AUTOSAR XML (schema 4-2-1)
package /ComponentTypes
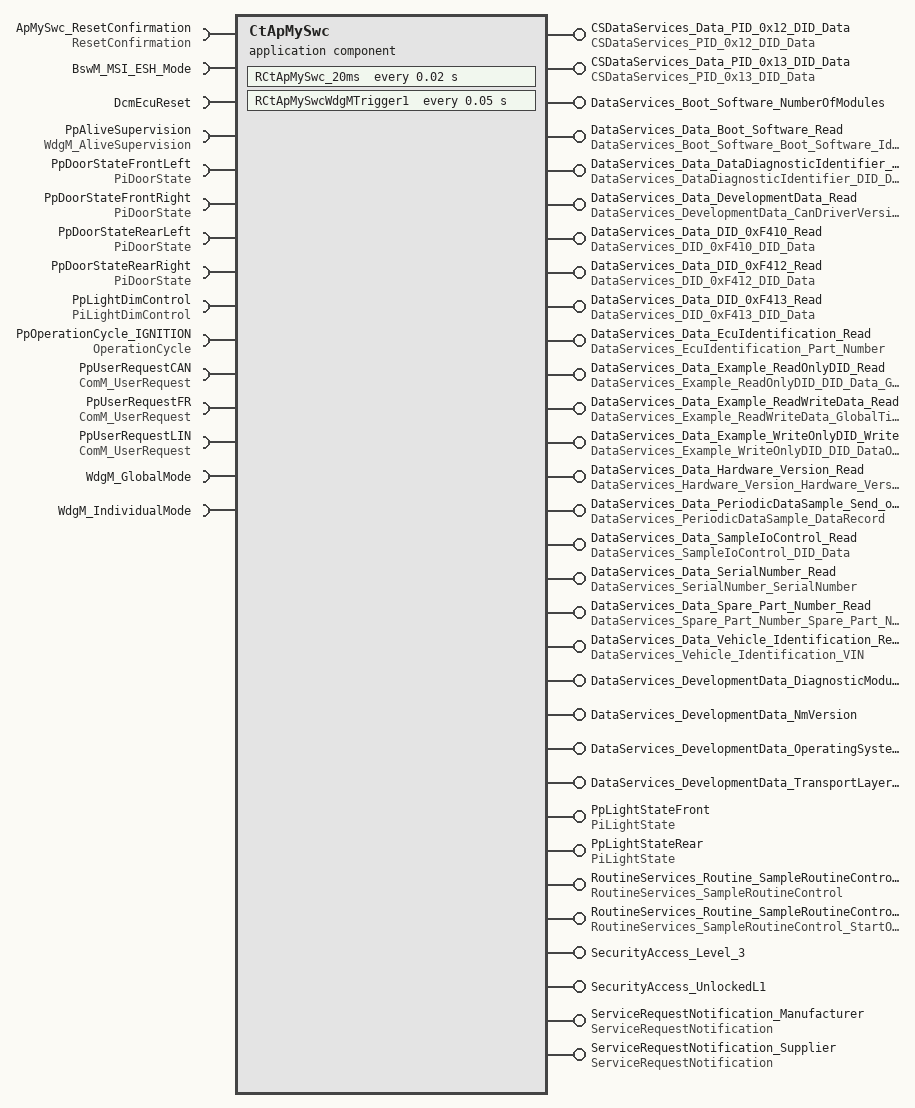
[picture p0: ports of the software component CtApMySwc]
  application sw component type CtApMySwc
    31 x provide port:
      CSDataServices_Data_PID_0x12_DID_Data: server-com-spec{operation=ReadData, queue-length=1}, provided-interface=CSDataServices_PID_0x12_DID_Data
      CSDataServices_Data_PID_0x13_DID_Data: server-com-spec{operation=ReadData, queue-length=1}, provided-interface=CSDataServices_PID_0x13_DID_Data
      DataServices_Boot_Software_NumberOfModules: provided-interface=DataServices_Boot_Software_NumberOfModules
        provided-com-specs:
          operation=ConditionCheckRead, queue-length=1
          operation=ReadData, queue-length=1
          operation=WriteData, queue-length=1
      DataServices_Data_Boot_Software_Read: provided-interface=DataServices_Boot_Software_Boot_Software_Identification
        provided-com-specs:
          operation=ConditionCheckRead, queue-length=1
          operation=ReadData, queue-length=1
          operation=WriteData, queue-length=1
      DataServices_Data_DataDiagnosticIdentifier_DID_Read: provided-interface=DataServices_DataDiagnosticIdentifier_DID_DataDiagnosticIdentifier
        provided-com-specs:
          operation=ConditionCheckRead, queue-length=1
          operation=ReadData, queue-length=1
          operation=WriteData, queue-length=1
      DataServices_Data_DevelopmentData_Read: provided-interface=DataServices_DevelopmentData_CanDriverVersion
        provided-com-specs:
          operation=ConditionCheckRead, queue-length=1
          operation=ReadData, queue-length=1
          operation=WriteData, queue-length=1
      DataServices_Data_DID_0xF410_Read: provided-com-specs=[{operation=ConditionCheckRead, queue-length=1}, {operation=ReadData, queue-length=1}], provided-interface=DataServices_DID_0xF410_DID_Data
      DataServices_Data_DID_0xF412_Read: provided-com-specs=[{operation=ConditionCheckRead, queue-length=1}, {operation=ReadData, queue-length=1}], provided-interface=DataServices_DID_0xF412_DID_Data
      DataServices_Data_DID_0xF413_Read: provided-com-specs=[{operation=ConditionCheckRead, queue-length=1}, {operation=ReadData, queue-length=1}], provided-interface=DataServices_DID_0xF413_DID_Data
      DataServices_Data_EcuIdentification_Read: provided-interface=DataServices_EcuIdentification_Part_Number
        provided-com-specs:
          operation=ConditionCheckRead, queue-length=1
          operation=ReadData, queue-length=1
          operation=WriteData, queue-length=1
      DataServices_Data_Example_ReadOnlyDID_Read: provided-com-specs=[{operation=ConditionCheckRead, queue-length=1}, {operation=ReadData, queue-length=1}], provided-interface=DataServices_Example_ReadOnlyDID_DID_Data_GlobalTime
      DataServices_Data_Example_ReadWriteData_Read: provided-interface=DataServices_Example_ReadWriteData_GlobalTime
        provided-com-specs:
          operation=ConditionCheckRead, queue-length=1
          operation=ReadData, queue-length=1
          operation=WriteData, queue-length=1
      DataServices_Data_Example_WriteOnlyDID_Write: server-com-spec{operation=WriteData, queue-length=1}, provided-interface=DataServices_Example_WriteOnlyDID_DID_DataObject
      DataServices_Data_Hardware_Version_Read: provided-interface=DataServices_Hardware_Version_Hardware_Version_Number
        provided-com-specs:
          operation=ConditionCheckRead, queue-length=1
          operation=ReadData, queue-length=1
          operation=WriteData, queue-length=1
      DataServices_Data_PeriodicDataSample_Send_once: provided-com-specs=[{operation=ConditionCheckRead, queue-length=1}, {operation=ReadData, queue-length=1}], provided-interface=DataServices_PeriodicDataSample_DataRecord
      DataServices_Data_SampleIoControl_Read: provided-interface=DataServices_SampleIoControl_DID_Data
        provided-com-specs:
          operation=FreezeCurrentState, queue-length=1
          operation=ReadData, queue-length=1
          operation=ResetToDefault, queue-length=1
          operation=ReturnControlToECU, queue-length=1
          operation=ShortTermAdjustment, queue-length=1
      DataServices_Data_SerialNumber_Read: provided-interface=DataServices_SerialNumber_SerialNumber
        provided-com-specs:
          operation=ConditionCheckRead, queue-length=1
          operation=ReadData, queue-length=1
          operation=WriteData, queue-length=1
      DataServices_Data_Spare_Part_Number_Read: provided-interface=DataServices_Spare_Part_Number_Spare_Part_Number
        provided-com-specs:
          operation=ConditionCheckRead, queue-length=1
          operation=ReadData, queue-length=1
          operation=WriteData, queue-length=1
      DataServices_Data_Vehicle_Identification_Read: provided-interface=DataServices_Vehicle_Identification_VIN
        provided-com-specs:
          operation=ConditionCheckRead, queue-length=1
          operation=ReadData, queue-length=1
          operation=WriteData, queue-length=1
      DataServices_DevelopmentData_DiagnosticModuleVersion: provided-interface=DataServices_DevelopmentData_DiagnosticModuleVersion
        provided-com-specs:
          operation=ConditionCheckRead, queue-length=1
          operation=ReadData, queue-length=1
          operation=WriteData, queue-length=1
      DataServices_DevelopmentData_NmVersion: provided-interface=DataServices_DevelopmentData_NmVersion
        provided-com-specs:
          operation=ConditionCheckRead, queue-length=1
          operation=ReadData, queue-length=1
          operation=WriteData, queue-length=1
      DataServices_DevelopmentData_OperatingSystemVersion: provided-interface=DataServices_DevelopmentData_OperatingSystemVersion
        provided-com-specs:
          operation=ConditionCheckRead, queue-length=1
          operation=ReadData, queue-length=1
          operation=WriteData, queue-length=1
      DataServices_DevelopmentData_TransportLayerVersion: provided-interface=DataServices_DevelopmentData_TransportLayerVersion
        provided-com-specs:
          operation=ConditionCheckRead, queue-length=1
          operation=ReadData, queue-length=1
          operation=WriteData, queue-length=1
      PpLightStateFront: nonqueued-sender-com-spec{data-element=DeLightState, init-value=constant-reference=CLightOff}, provided-interface=PiLightState
      PpLightStateRear: nonqueued-sender-com-spec{data-element=DeLightState, init-value=constant-reference=CLightOff}, provided-interface=PiLightState
      RoutineServices_Routine_SampleRoutineControl_Start: provided-interface=RoutineServices_SampleRoutineControl
        provided-com-specs:
          operation=RequestResults, queue-length=1
          operation=Start, queue-length=1
          operation=Stop, queue-length=1
      RoutineServices_Routine_SampleRoutineControl_StartOnly_Start: provided-com-specs=[{operation=RequestResults, queue-length=1}, {operation=Start, queue-length=1}], provided-interface=RoutineServices_SampleRoutineControl_StartOnly
      SecurityAccess_Level_3: provided-com-specs=[{operation=CompareKey, queue-length=1}, {operation=GetSeed, queue-length=1}], provided-interface=SecurityAccess_Level_3
      SecurityAccess_UnlockedL1: provided-com-specs=[{operation=CompareKey, queue-length=1}, {operation=GetSeed, queue-length=1}], provided-interface=SecurityAccess_UnlockedL1
      ServiceRequestNotification_Manufacturer: provided-com-specs=[{operation=Confirmation, queue-length=1}, {operation=Indication, queue-length=1}], provided-interface=ServiceRequestNotification
      ServiceRequestNotification_Supplier: provided-com-specs=[{operation=Confirmation, queue-length=1}, {operation=Indication, queue-length=1}], provided-interface=ServiceRequestNotification
    15 x require port:
      ApMySwc_ResetConfirmation: client-com-spec=ConfirmReset, required-interface=ResetConfirmation
      BswM_MSI_ESH_Mode: mode-switch-receiver-com-spec{enhanced-mode-api=false, supports-asynchronous-mode-switch=false}, required-interface=BswM_MSI_ESH_Mode
      DcmEcuReset: mode-switch-receiver-com-spec{enhanced-mode-api=false, supports-asynchronous-mode-switch=false}, required-interface=DcmEcuReset
      PpAliveSupervision: client-com-spec=CheckpointReached, required-interface=WdgM_AliveSupervision
      PpDoorStateFrontLeft: nonqueued-receiver-com-spec{data-element=DeDoorState, filter=data-filter-type=ALWAYS, init-value=constant-reference=CDoorClosed}, required-interface=PiDoorState
      PpDoorStateFrontRight: nonqueued-receiver-com-spec{data-element=DeDoorState, filter=data-filter-type=ALWAYS, init-value=constant-reference=CDoorClosed}, required-interface=PiDoorState
      PpDoorStateRearLeft: nonqueued-receiver-com-spec{data-element=DeDoorState, filter=data-filter-type=ALWAYS, init-value=constant-reference=CDoorClosed}, required-interface=PiDoorState
      PpDoorStateRearRight: nonqueued-receiver-com-spec{data-element=DeDoorState, filter=data-filter-type=ALWAYS, init-value=constant-reference=CDoorClosed}, required-interface=PiDoorState
      PpLightDimControl: nonqueued-receiver-com-spec{data-element=DeLightDimCtrl, filter=data-filter-type=ALWAYS, init-value=constant-reference=CBackLightDimCtrlInit}, required-interface=PiLightDimControl
      PpOperationCycle_IGNITION: required-com-specs=[GetOperationCycleState, SetOperationCycleState], required-interface=OperationCycle
      PpUserRequestCAN: required-com-specs=[GetCurrentComMode, GetMaxComMode, GetRequestedComMode, RequestComMode], required-interface=ComM_UserRequest
      PpUserRequestFR: required-com-specs=[GetCurrentComMode, GetMaxComMode, GetRequestedComMode, RequestComMode], required-interface=ComM_UserRequest
      PpUserRequestLIN: required-com-specs=[GetCurrentComMode, GetMaxComMode, GetRequestedComMode, RequestComMode], required-interface=ComM_UserRequest
      WdgM_GlobalMode: mode-switch-receiver-com-spec{enhanced-mode-api=false, supports-asynchronous-mode-switch=false}, required-interface=WdgM_GlobalMode
      WdgM_IndividualMode: mode-switch-receiver-com-spec{enhanced-mode-api=false, supports-asynchronous-mode-switch=false}, required-interface=WdgM_IndividualMode
    behavior CtApMySwc_InternalBehavior: data-type-mapping=DemoTypeMapping
      60 x operation invoked event:
        OIT_CtApMySwc_CSDataServices_Data_PID_0x12_DID_Data_ReadData_CSDataServices_Data_PID_0x12_DID_Data_ReadData: start-on-event=CtApMySwc_CSDataServices_Data_PID_0x12_DID_Data_ReadData, operation=CSDataServices_Data_PID_0x12_DID_Data.ReadData
        OIT_CtApMySwc_CSDataServices_Data_PID_0x13_DID_Data_ReadData_CSDataServices_Data_PID_0x13_DID_Data_ReadData: start-on-event=CtApMySwc_CSDataServices_Data_PID_0x13_DID_Data_ReadData, operation=CSDataServices_Data_PID_0x13_DID_Data.ReadData
        OIT_CtApMySwc_DataServices_Boot_Software_NumberOfModules_ConditionCheckRead_DataServices_Boot_Software_NumberOfModules_C3D9222EE: start-on-event=CtApMySwc_DataServices_Boot_Software_NumberOfModules_ConditionCheckRead, operation=DataServices_Boot_Software_NumberOfModules.ConditionCheckRead
        OIT_CtApMySwc_DataServices_Boot_Software_NumberOfModules_ReadData_DataServices_Boot_Software_NumberOfModules_ReadData: start-on-event=CtApMySwc_DataServices_Boot_Software_NumberOfModules_ReadData, operation=DataServices_Boot_Software_NumberOfModules.ReadData
        OIT_CtApMySwc_DataServices_Boot_Software_NumberOfModules_WriteData_DataServices_Boot_Software_NumberOfModules_WriteData: start-on-event=CtApMySwc_DataServices_Boot_Software_NumberOfModules_WriteData, operation=DataServices_Boot_Software_NumberOfModules.WriteData
        OIT_CtApMySwc_DataServices_Data_Boot_Software_ConditionCheckRead_DataServices_Data_Boot_Software_Read_ConditionCheckRead: start-on-event=CtApMySwc_DataServices_Data_Boot_Software_ConditionCheckRead, operation=DataServices_Data_Boot_Software_Read.ConditionCheckRead
        OIT_CtApMySwc_DataServices_Data_Boot_Software_ReadData_DataServices_Data_Boot_Software_Read_ReadData: start-on-event=CtApMySwc_DataServices_Data_Boot_Software_ReadData, operation=DataServices_Data_Boot_Software_Read.ReadData
        OIT_CtApMySwc_DataServices_Data_Boot_Software_WriteData_DataServices_Data_Boot_Software_Read_WriteData: start-on-event=CtApMySwc_DataServices_Data_Boot_Software_WriteData, operation=DataServices_Data_Boot_Software_Read.WriteData
        OIT_CtApMySwc_DataServices_Data_DataDiagnosticIdentifier_DID_ConditionCheckRead_DataServices_Data_DataDiagnosticIdentifi7C394B35: start-on-event=CtApMySwc_DataServices_Data_DataDiagnosticIdentifier_DID_ConditionCheckRead, operation=DataServices_Data_DataDiagnosticIdentifier_DID_Read.ConditionCheckRead
        OIT_CtApMySwc_DataServices_Data_DataDiagnosticIdentifier_DID_ReadData_DataServices_Data_DataDiagnosticIdentifier_DID_Rea6AA9561D: start-on-event=CtApMySwc_DataServices_Data_DataDiagnosticIdentifier_DID_ReadData, operation=DataServices_Data_DataDiagnosticIdentifier_DID_Read.ReadData
        OIT_CtApMySwc_DataServices_Data_DataDiagnosticIdentifier_DID_WriteData_DataServices_Data_DataDiagnosticIdentifier_DID_ReCD38CD1D: start-on-event=CtApMySwc_DataServices_Data_DataDiagnosticIdentifier_DID_WriteData, operation=DataServices_Data_DataDiagnosticIdentifier_DID_Read.WriteData
        OIT_CtApMySwc_DataServices_Data_DevelopmentData_ConditionCheckRead_DataServices_Data_DevelopmentData_Read_ConditionCheckRead: start-on-event=CtApMySwc_DataServices_Data_DevelopmentData_ConditionCheckRead, operation=DataServices_Data_DevelopmentData_Read.ConditionCheckRead
        OIT_CtApMySwc_DataServices_Data_DevelopmentData_ReadData_DataServices_Data_DevelopmentData_Read_ReadData: start-on-event=CtApMySwc_DataServices_Data_DevelopmentData_ReadData, operation=DataServices_Data_DevelopmentData_Read.ReadData
        OIT_CtApMySwc_DataServices_Data_DevelopmentData_WriteData_DataServices_Data_DevelopmentData_Read_WriteData: start-on-event=CtApMySwc_DataServices_Data_DevelopmentData_WriteData, operation=DataServices_Data_DevelopmentData_Read.WriteData
        OIT_CtApMySwc_DataServices_Data_DID_0xF410_ConditionCheckRead_DataServices_Data_DID_0xF410_Read_ConditionCheckRead: start-on-event=CtApMySwc_DataServices_Data_DID_0xF410_ConditionCheckRead, operation=DataServices_Data_DID_0xF410_Read.ConditionCheckRead
        OIT_CtApMySwc_DataServices_Data_DID_0xF410_ReadData_DataServices_Data_DID_0xF410_Read_ReadData: start-on-event=CtApMySwc_DataServices_Data_DID_0xF410_ReadData, operation=DataServices_Data_DID_0xF410_Read.ReadData
        OIT_CtApMySwc_DataServices_Data_DID_0xF412_ConditionCheckRead_DataServices_Data_DID_0xF412_Read_ConditionCheckRead: start-on-event=CtApMySwc_DataServices_Data_DID_0xF412_ConditionCheckRead, operation=DataServices_Data_DID_0xF412_Read.ConditionCheckRead
        OIT_CtApMySwc_DataServices_Data_DID_0xF412_ReadData_DataServices_Data_DID_0xF412_Read_ReadData: start-on-event=CtApMySwc_DataServices_Data_DID_0xF412_ReadData, operation=DataServices_Data_DID_0xF412_Read.ReadData
        OIT_CtApMySwc_DataServices_Data_DID_0xF413_ConditionCheckRead_DataServices_Data_DID_0xF413_Read_ConditionCheckRead: start-on-event=CtApMySwc_DataServices_Data_DID_0xF413_ConditionCheckRead, operation=DataServices_Data_DID_0xF413_Read.ConditionCheckRead
        OIT_CtApMySwc_DataServices_Data_DID_0xF413_ReadData_DataServices_Data_DID_0xF413_Read_ReadData: start-on-event=CtApMySwc_DataServices_Data_DID_0xF413_ReadData, operation=DataServices_Data_DID_0xF413_Read.ReadData
        OIT_CtApMySwc_DataServices_Data_EcuIdentification_ConditionCheckRead_DataServices_Data_EcuIdentification_Read_ConditionCheckRead: start-on-event=CtApMySwc_DataServices_Data_EcuIdentification_ConditionCheckRead, operation=DataServices_Data_EcuIdentification_Read.ConditionCheckRead
        OIT_CtApMySwc_DataServices_Data_EcuIdentification_ReadData_DataServices_Data_EcuIdentification_Read_ReadData: start-on-event=CtApMySwc_DataServices_Data_EcuIdentification_ReadData, operation=DataServices_Data_EcuIdentification_Read.ReadData
        OIT_CtApMySwc_DataServices_Data_EcuIdentification_WriteData_DataServices_Data_EcuIdentification_Read_WriteData: start-on-event=CtApMySwc_DataServices_Data_EcuIdentification_WriteData, operation=DataServices_Data_EcuIdentification_Read.WriteData
        OIT_CtApMySwc_DataServices_Data_Example_ReadOnlyDID_ConditionCheckRead_DataServices_Data_Example_ReadOnlyDID_Read_ConditAC8C6CD3: start-on-event=CtApMySwc_DataServices_Data_Example_ReadOnlyDID_ConditionCheckRead, operation=DataServices_Data_Example_ReadOnlyDID_Read.ConditionCheckRead
        OIT_CtApMySwc_DataServices_Data_Example_ReadOnlyDID_ReadData_DataServices_Data_Example_ReadOnlyDID_Read_ReadData: start-on-event=CtApMySwc_DataServices_Data_Example_ReadOnlyDID_ReadData, operation=DataServices_Data_Example_ReadOnlyDID_Read.ReadData
        OIT_CtApMySwc_DataServices_Data_Example_ReadWriteData_ConditionCheckRead_DataServices_Data_Example_ReadWriteData_Read_Co3BD509C9: start-on-event=CtApMySwc_DataServices_Data_Example_ReadWriteData_ConditionCheckRead, operation=DataServices_Data_Example_ReadWriteData_Read.ConditionCheckRead
        OIT_CtApMySwc_DataServices_Data_Example_ReadWriteData_ReadData_DataServices_Data_Example_ReadWriteData_Read_ReadData: start-on-event=CtApMySwc_DataServices_Data_Example_ReadWriteData_ReadData, operation=DataServices_Data_Example_ReadWriteData_Read.ReadData
        OIT_CtApMySwc_DataServices_Data_Example_ReadWriteData_WriteData_DataServices_Data_Example_ReadWriteData_Read_WriteData: start-on-event=CtApMySwc_DataServices_Data_Example_ReadWriteData_WriteData, operation=DataServices_Data_Example_ReadWriteData_Read.WriteData
        OIT_CtApMySwc_DataServices_Data_Example_WriteOnlyDID_WriteData_DataServices_Data_Example_WriteOnlyDID_Write_WriteData: start-on-event=CtApMySwc_DataServices_Data_Example_WriteOnlyDID_WriteData, operation=DataServices_Data_Example_WriteOnlyDID_Write.WriteData
        OIT_CtApMySwc_DataServices_Data_Hardware_Version_ConditionCheckRead_DataServices_Data_Hardware_Version_Read_ConditionCheckRead: start-on-event=CtApMySwc_DataServices_Data_Hardware_Version_ConditionCheckRead, operation=DataServices_Data_Hardware_Version_Read.ConditionCheckRead
        OIT_CtApMySwc_DataServices_Data_Hardware_Version_ReadData_DataServices_Data_Hardware_Version_Read_ReadData: start-on-event=CtApMySwc_DataServices_Data_Hardware_Version_ReadData, operation=DataServices_Data_Hardware_Version_Read.ReadData
        OIT_CtApMySwc_DataServices_Data_Hardware_Version_WriteData_DataServices_Data_Hardware_Version_Read_WriteData: start-on-event=CtApMySwc_DataServices_Data_Hardware_Version_WriteData, operation=DataServices_Data_Hardware_Version_Read.WriteData
        OIT_CtApMySwc_DataServices_Data_PeriodicDataSample_ConditionCheckRead_DataServices_Data_PeriodicDataSample_Send_once_ConDEAB29DB: start-on-event=CtApMySwc_DataServices_Data_PeriodicDataSample_ConditionCheckRead, operation=DataServices_Data_PeriodicDataSample_Send_once.ConditionCheckRead
        OIT_CtApMySwc_DataServices_Data_PeriodicDataSample_ReadData_DataServices_Data_PeriodicDataSample_Send_once_ReadData: start-on-event=CtApMySwc_DataServices_Data_PeriodicDataSample_ReadData, operation=DataServices_Data_PeriodicDataSample_Send_once.ReadData
        OIT_CtApMySwc_DataServices_Data_SampleIoControl_FreezeCurrentState_DataServices_Data_SampleIoControl_Read_FreezeCurrentState: start-on-event=CtApMySwc_DataServices_Data_SampleIoControl_FreezeCurrentState, operation=DataServices_Data_SampleIoControl_Read.FreezeCurrentState
        OIT_CtApMySwc_DataServices_Data_SampleIoControl_ReadData_DataServices_Data_SampleIoControl_Read_ReadData: start-on-event=CtApMySwc_DataServices_Data_SampleIoControl_ReadData, operation=DataServices_Data_SampleIoControl_Read.ReadData
        OIT_CtApMySwc_DataServices_Data_SampleIoControl_ResetToDefault_DataServices_Data_SampleIoControl_Read_ResetToDefault: start-on-event=CtApMySwc_DataServices_Data_SampleIoControl_ResetToDefault, operation=DataServices_Data_SampleIoControl_Read.ResetToDefault
        OIT_CtApMySwc_DataServices_Data_SampleIoControl_ReturnControlToECU_DataServices_Data_SampleIoControl_Read_ReturnControlToECU: start-on-event=CtApMySwc_DataServices_Data_SampleIoControl_ReturnControlToECU, operation=DataServices_Data_SampleIoControl_Read.ReturnControlToECU
        OIT_CtApMySwc_DataServices_Data_SampleIoControl_ShortTermAdjustment_DataServices_Data_SampleIoControl_Read_ShortTermAdjustment: start-on-event=CtApMySwc_DataServices_Data_SampleIoControl_ShortTermAdjustment, operation=DataServices_Data_SampleIoControl_Read.ShortTermAdjustment
        OIT_CtApMySwc_DataServices_Data_SerialNumber_ConditionCheckRead_DataServices_Data_SerialNumber_Read_ConditionCheckRead: start-on-event=CtApMySwc_DataServices_Data_SerialNumber_ConditionCheckRead, operation=DataServices_Data_SerialNumber_Read.ConditionCheckRead
        OIT_CtApMySwc_DataServices_Data_SerialNumber_ReadData_DataServices_Data_SerialNumber_Read_ReadData: start-on-event=CtApMySwc_DataServices_Data_SerialNumber_ReadData, operation=DataServices_Data_SerialNumber_Read.ReadData
        OIT_CtApMySwc_DataServices_Data_SerialNumber_WriteData_DataServices_Data_SerialNumber_Read_WriteData: start-on-event=CtApMySwc_DataServices_Data_SerialNumber_WriteData, operation=DataServices_Data_SerialNumber_Read.WriteData
        OIT_CtApMySwc_DataServices_Data_Spare_Part_Number_ConditionCheckRead_DataServices_Data_Spare_Part_Number_Read_ConditionCheckRead: start-on-event=CtApMySwc_DataServices_Data_Spare_Part_Number_ConditionCheckRead, operation=DataServices_Data_Spare_Part_Number_Read.ConditionCheckRead
        OIT_CtApMySwc_DataServices_Data_Spare_Part_Number_ReadData_DataServices_Data_Spare_Part_Number_Read_ReadData: start-on-event=CtApMySwc_DataServices_Data_Spare_Part_Number_ReadData, operation=DataServices_Data_Spare_Part_Number_Read.ReadData
        OIT_CtApMySwc_DataServices_Data_Spare_Part_Number_WriteData_DataServices_Data_Spare_Part_Number_Read_WriteData: start-on-event=CtApMySwc_DataServices_Data_Spare_Part_Number_WriteData, operation=DataServices_Data_Spare_Part_Number_Read.WriteData
        OIT_CtApMySwc_DataServices_Data_Vehicle_Identification_ConditionCheckRead_DataServices_Data_Vehicle_Identification_Read_5BBB2A2C: start-on-event=CtApMySwc_DataServices_Data_Vehicle_Identification_ConditionCheckRead, operation=DataServices_Data_Vehicle_Identification_Read.ConditionCheckRead
        OIT_CtApMySwc_DataServices_Data_Vehicle_Identification_ReadData_DataServices_Data_Vehicle_Identification_Read_ReadData: start-on-event=CtApMySwc_DataServices_Data_Vehicle_Identification_ReadData, operation=DataServices_Data_Vehicle_Identification_Read.ReadData
        OIT_CtApMySwc_DataServices_Data_Vehicle_Identification_WriteData_DataServices_Data_Vehicle_Identification_Read_WriteData: start-on-event=CtApMySwc_DataServices_Data_Vehicle_Identification_WriteData, operation=DataServices_Data_Vehicle_Identification_Read.WriteData
        OIT_CtApMySwc_DataServices_DevelopmentData_DiagnosticModuleVersion_ConditionCheckRead_DataServices_DevelopmentData_Diagn5CC3F13A: start-on-event=CtApMySwc_DataServices_DevelopmentData_DiagnosticModuleVersion_ConditionCheckRead, operation=DataServices_DevelopmentData_DiagnosticModuleVersion.ConditionCheckRead
        OIT_CtApMySwc_DataServices_DevelopmentData_DiagnosticModuleVersion_ReadData_DataServices_DevelopmentData_DiagnosticModulF7EC85FA: start-on-event=CtApMySwc_DataServices_DevelopmentData_DiagnosticModuleVersion_ReadData, operation=DataServices_DevelopmentData_DiagnosticModuleVersion.ReadData
        OIT_CtApMySwc_DataServices_DevelopmentData_DiagnosticModuleVersion_WriteData_DataServices_DevelopmentData_DiagnosticModu3CB1758A: start-on-event=CtApMySwc_DataServices_DevelopmentData_DiagnosticModuleVersion_WriteData, operation=DataServices_DevelopmentData_DiagnosticModuleVersion.WriteData
        OIT_CtApMySwc_DataServices_DevelopmentData_NmVersion_ConditionCheckRead_DataServices_DevelopmentData_NmVersion_ConditionA9EB025F: start-on-event=CtApMySwc_DataServices_DevelopmentData_NmVersion_ConditionCheckRead, operation=DataServices_DevelopmentData_NmVersion.ConditionCheckRead
        OIT_CtApMySwc_DataServices_DevelopmentData_NmVersion_ReadData_DataServices_DevelopmentData_NmVersion_ReadData: start-on-event=CtApMySwc_DataServices_DevelopmentData_NmVersion_ReadData, operation=DataServices_DevelopmentData_NmVersion.ReadData
        OIT_CtApMySwc_DataServices_DevelopmentData_NmVersion_WriteData_DataServices_DevelopmentData_NmVersion_WriteData: start-on-event=CtApMySwc_DataServices_DevelopmentData_NmVersion_WriteData, operation=DataServices_DevelopmentData_NmVersion.WriteData
        OIT_CtApMySwc_DataServices_DevelopmentData_OperatingSystemVersion_ConditionCheckRead_DataServices_DevelopmentData_Operat804E2BAF: start-on-event=CtApMySwc_DataServices_DevelopmentData_OperatingSystemVersion_ConditionCheckRead, operation=DataServices_DevelopmentData_OperatingSystemVersion.ConditionCheckRead
        OIT_CtApMySwc_DataServices_DevelopmentData_OperatingSystemVersion_ReadData_DataServices_DevelopmentData_OperatingSystemV5FD7B806: start-on-event=CtApMySwc_DataServices_DevelopmentData_OperatingSystemVersion_ReadData, operation=DataServices_DevelopmentData_OperatingSystemVersion.ReadData
        OIT_CtApMySwc_DataServices_DevelopmentData_OperatingSystemVersion_WriteData_DataServices_DevelopmentData_OperatingSystem956672CC: start-on-event=CtApMySwc_DataServices_DevelopmentData_OperatingSystemVersion_WriteData, operation=DataServices_DevelopmentData_OperatingSystemVersion.WriteData
        OIT_CtApMySwc_DataServices_DevelopmentData_TransportLayerVersion_ConditionCheckRead_DataServices_DevelopmentData_TranspoC0DAFF6E: start-on-event=CtApMySwc_DataServices_DevelopmentData_TransportLayerVersion_ConditionCheckRead, operation=DataServices_DevelopmentData_TransportLayerVersion.ConditionCheckRead
        OIT_CtApMySwc_DataServices_DevelopmentData_TransportLayerVersion_ReadData_DataServices_DevelopmentData_TransportLayerVerE5582B0A: start-on-event=CtApMySwc_DataServices_DevelopmentData_TransportLayerVersion_ReadData, operation=DataServices_DevelopmentData_TransportLayerVersion.ReadData
        OIT_CtApMySwc_DataServices_DevelopmentData_TransportLayerVersion_WriteData_DataServices_DevelopmentData_TransportLayerVeCF447876: start-on-event=CtApMySwc_DataServices_DevelopmentData_TransportLayerVersion_WriteData, operation=DataServices_DevelopmentData_TransportLayerVersion.WriteData
      init event CtApMySwc_InitEvent: start-on-event=CtApMySwc_Init
      9 x operation invoked event:
        OIT_CtApMySwc_RoutineServices_Routine_SampleRoutineControl_RequestResults_RoutineServices_Routine_SampleRoutineControl_SC820A625: start-on-event=CtApMySwc_RoutineServices_Routine_SampleRoutineControl_RequestResults, operation=RoutineServices_Routine_SampleRoutineControl_Start.RequestResults
        OIT_CtApMySwc_RoutineServices_Routine_SampleRoutineControl_Start_RoutineServices_Routine_SampleRoutineControl_Start_Start: start-on-event=CtApMySwc_RoutineServices_Routine_SampleRoutineControl_Start, operation=RoutineServices_Routine_SampleRoutineControl_Start.Start
        OIT_CtApMySwc_RoutineServices_Routine_SampleRoutineControl_StartOnly_RequestResults_RoutineServices_Routine_SampleRoutinAAF2470C: start-on-event=CtApMySwc_RoutineServices_Routine_SampleRoutineControl_StartOnly_RequestResults, operation=RoutineServices_Routine_SampleRoutineControl_StartOnly_Start.RequestResults
        OIT_CtApMySwc_RoutineServices_Routine_SampleRoutineControl_StartOnly_Start_RoutineServices_Routine_SampleRoutineControl_5C795508: start-on-event=CtApMySwc_RoutineServices_Routine_SampleRoutineControl_StartOnly_Start, operation=RoutineServices_Routine_SampleRoutineControl_StartOnly_Start.Start
        OIT_CtApMySwc_RoutineServices_Routine_SampleRoutineControl_Stop_RoutineServices_Routine_SampleRoutineControl_Start_Stop: start-on-event=CtApMySwc_RoutineServices_Routine_SampleRoutineControl_Stop, operation=RoutineServices_Routine_SampleRoutineControl_Start.Stop
        OIT_CtApMySwc_SecurityAccess_Level_3_CompareKey_SecurityAccess_Level_3_CompareKey: start-on-event=CtApMySwc_SecurityAccess_Level_3_CompareKey, operation=SecurityAccess_Level_3.CompareKey
        OIT_CtApMySwc_SecurityAccess_Level_3_GetSeed_SecurityAccess_Level_3_GetSeed: start-on-event=CtApMySwc_SecurityAccess_Level_3_GetSeed, operation=SecurityAccess_Level_3.GetSeed
        OIT_CtApMySwc_SecurityAccess_UnlockedL1_CompareKey_SecurityAccess_UnlockedL1_CompareKey: start-on-event=CtApMySwc_SecurityAccess_UnlockedL1_CompareKey, operation=SecurityAccess_UnlockedL1.CompareKey
        OIT_CtApMySwc_SecurityAccess_UnlockedL1_GetSeed_SecurityAccess_UnlockedL1_GetSeed: start-on-event=CtApMySwc_SecurityAccess_UnlockedL1_GetSeed, operation=SecurityAccess_UnlockedL1.GetSeed
      timing event TMT_mySwcRunnable: start-on-event=RCtApMySwc_20ms, period=0.02
        disabled-mode:
          BswM_MSI_ESH_Mode.BswM_MDGP_ESH_Mode.SHUTDOWN
          BswM_MSI_ESH_Mode.BswM_MDGP_ESH_Mode.STARTUP
          BswM_MSI_ESH_Mode.BswM_MDGP_ESH_Mode.WAKEUP
      timing event TMT_WdgM_Trigger1: start-on-event=RCtApMySwcWdgMTrigger1, period=0.05
      swc mode switch event MST_ResetEcu_0: start-on-event=ResetEcu, activation=ON-ENTRY, mode=DcmEcuReset.DcmEcuReset.EXECUTE
      4 x operation invoked event:
        OIT_ServiceRequestNotification_Confirmation_ServiceRequestNotification_Confirmation: start-on-event=ServiceRequestNotification_Confirmation, operation=ServiceRequestNotification_Manufacturer.Confirmation
        OIT_ServiceRequestNotification_Indication_ServiceRequestNotification_Indication: start-on-event=ServiceRequestNotification_Indication, operation=ServiceRequestNotification_Manufacturer.Indication
        OIT_ServiceRequestNotification_Supplier_Confirmation_ServiceRequestNotification_Supplier_Confirmation: start-on-event=ServiceRequestNotification_Supplier_Confirmation, operation=ServiceRequestNotification_Supplier.Confirmation
        OIT_ServiceRequestNotification_Supplier_Indication_ServiceRequestNotification_Supplier_Indication: start-on-event=ServiceRequestNotification_Supplier_Indication, operation=ServiceRequestNotification_Supplier.Indication
      explicit-inter-runnable-variables:
        data irvDoorOldState: type=uint8, init-value=0
        data irvOdometer: type=uint16, init-value=0
      77 x runnable:
        CtApMySwc_CSDataServices_Data_PID_0x12_DID_Data_ReadData
        CtApMySwc_CSDataServices_Data_PID_0x13_DID_Data_ReadData
        CtApMySwc_DataServices_Boot_Software_NumberOfModules_ConditionCheckRead
        CtApMySwc_DataServices_Boot_Software_NumberOfModules_ReadData
        CtApMySwc_DataServices_Boot_Software_NumberOfModules_WriteData
        CtApMySwc_DataServices_Data_Boot_Software_ConditionCheckRead
        CtApMySwc_DataServices_Data_Boot_Software_ReadData
        CtApMySwc_DataServices_Data_Boot_Software_WriteData
        CtApMySwc_DataServices_Data_DataDiagnosticIdentifier_DID_ConditionCheckRead
        CtApMySwc_DataServices_Data_DataDiagnosticIdentifier_DID_ReadData
        CtApMySwc_DataServices_Data_DataDiagnosticIdentifier_DID_WriteData
        CtApMySwc_DataServices_Data_DevelopmentData_ConditionCheckRead
        CtApMySwc_DataServices_Data_DevelopmentData_ReadData
        CtApMySwc_DataServices_Data_DevelopmentData_WriteData
        CtApMySwc_DataServices_Data_DID_0xF410_ConditionCheckRead
        CtApMySwc_DataServices_Data_DID_0xF410_ReadData
        CtApMySwc_DataServices_Data_DID_0xF412_ConditionCheckRead
        CtApMySwc_DataServices_Data_DID_0xF412_ReadData
        CtApMySwc_DataServices_Data_DID_0xF413_ConditionCheckRead
        CtApMySwc_DataServices_Data_DID_0xF413_ReadData
        CtApMySwc_DataServices_Data_EcuIdentification_ConditionCheckRead
        CtApMySwc_DataServices_Data_EcuIdentification_ReadData
        CtApMySwc_DataServices_Data_EcuIdentification_WriteData
        CtApMySwc_DataServices_Data_Example_ReadOnlyDID_ConditionCheckRead
        CtApMySwc_DataServices_Data_Example_ReadOnlyDID_ReadData
        CtApMySwc_DataServices_Data_Example_ReadWriteData_ConditionCheckRead
        CtApMySwc_DataServices_Data_Example_ReadWriteData_ReadData
        CtApMySwc_DataServices_Data_Example_ReadWriteData_WriteData
        CtApMySwc_DataServices_Data_Example_WriteOnlyDID_WriteData
        CtApMySwc_DataServices_Data_Hardware_Version_ConditionCheckRead
        CtApMySwc_DataServices_Data_Hardware_Version_ReadData
        CtApMySwc_DataServices_Data_Hardware_Version_WriteData
        CtApMySwc_DataServices_Data_PeriodicDataSample_ConditionCheckRead
        CtApMySwc_DataServices_Data_PeriodicDataSample_ReadData
        CtApMySwc_DataServices_Data_SampleIoControl_FreezeCurrentState
        CtApMySwc_DataServices_Data_SampleIoControl_ReadData
        CtApMySwc_DataServices_Data_SampleIoControl_ResetToDefault
        CtApMySwc_DataServices_Data_SampleIoControl_ReturnControlToECU
        CtApMySwc_DataServices_Data_SampleIoControl_ShortTermAdjustment
        CtApMySwc_DataServices_Data_SerialNumber_ConditionCheckRead
        CtApMySwc_DataServices_Data_SerialNumber_ReadData
        CtApMySwc_DataServices_Data_SerialNumber_WriteData
        CtApMySwc_DataServices_Data_Spare_Part_Number_ConditionCheckRead
        CtApMySwc_DataServices_Data_Spare_Part_Number_ReadData
        CtApMySwc_DataServices_Data_Spare_Part_Number_WriteData
        CtApMySwc_DataServices_Data_Vehicle_Identification_ConditionCheckRead
        CtApMySwc_DataServices_Data_Vehicle_Identification_ReadData
        CtApMySwc_DataServices_Data_Vehicle_Identification_WriteData
        CtApMySwc_DataServices_DevelopmentData_DiagnosticModuleVersion_ConditionCheckRead
        CtApMySwc_DataServices_DevelopmentData_DiagnosticModuleVersion_ReadData
        CtApMySwc_DataServices_DevelopmentData_DiagnosticModuleVersion_WriteData
        CtApMySwc_DataServices_DevelopmentData_NmVersion_ConditionCheckRead
        CtApMySwc_DataServices_DevelopmentData_NmVersion_ReadData
        CtApMySwc_DataServices_DevelopmentData_NmVersion_WriteData
        CtApMySwc_DataServices_DevelopmentData_OperatingSystemVersion_ConditionCheckRead
        CtApMySwc_DataServices_DevelopmentData_OperatingSystemVersion_ReadData
        CtApMySwc_DataServices_DevelopmentData_OperatingSystemVersion_WriteData
        CtApMySwc_DataServices_DevelopmentData_TransportLayerVersion_ConditionCheckRead
        CtApMySwc_DataServices_DevelopmentData_TransportLayerVersion_ReadData
        CtApMySwc_DataServices_DevelopmentData_TransportLayerVersion_WriteData
        CtApMySwc_Init
        CtApMySwc_RoutineServices_Routine_SampleRoutineControl_RequestResults
        CtApMySwc_RoutineServices_Routine_SampleRoutineControl_Start
        CtApMySwc_RoutineServices_Routine_SampleRoutineControl_StartOnly_RequestResults
        CtApMySwc_RoutineServices_Routine_SampleRoutineControl_StartOnly_Start
        CtApMySwc_RoutineServices_Routine_SampleRoutineControl_Stop
        CtApMySwc_SecurityAccess_Level_3_CompareKey
        CtApMySwc_SecurityAccess_Level_3_GetSeed
        CtApMySwc_SecurityAccess_UnlockedL1_CompareKey
        CtApMySwc_SecurityAccess_UnlockedL1_GetSeed
        RCtApMySwc_20ms: mode-access-points=[WdgM_GlobalMode.currentMode, WdgM_IndividualMode.currentMode]
          data-receive-point-by-arguments:
            5 x access:
              REC_Backlight_DimControl_Element: accessed-variable=PpLightDimControl.DeLightDimCtrl
              REC_PpDoorStateFrontLeft_Element: accessed-variable=PpDoorStateFrontLeft.DeDoorState
              REC_PpDoorStateFrontRight_Element: accessed-variable=PpDoorStateFrontRight.DeDoorState
              REC_PpDoorStateRearLeft_DoorState: accessed-variable=PpDoorStateRearLeft.DeDoorState
              REC_PpDoorStateRearRight_DoorState: accessed-variable=PpDoorStateRearRight.DeDoorState
          data-send-points:
            access SEND_PpRearLight_lightState: accessed-variable=PpLightStateRear.DeLightState
            access SEND_Set_FrontLightState_Element: accessed-variable=PpLightStateFront.DeLightState
          read-local-variables:
            access READ_irvDoorOldState: accessed-variable=irvDoorOldState
            access READ_irvOdometer: accessed-variable=irvOdometer
          7 x sync call, all with timeout=0:
            SC_ApMySwc_ResetConfirmation_ConfirmReset: operation=ApMySwc_ResetConfirmation.ConfirmReset
            SC_ComM_UserRequest_FR_RequestComMode: operation=PpUserRequestFR.RequestComMode
            SC_ComM_UserRequest_LIN_RequestComMode: operation=PpUserRequestLIN.RequestComMode
            SC_ComM_UserRequest_RequestComMode: operation=PpUserRequestCAN.RequestComMode
            SC_PpUserRequestCAN_GetRequestedComMode: operation=PpUserRequestCAN.GetRequestedComMode
            SC_PpUserRequestFR_GetCurrentComMode: operation=PpUserRequestFR.GetCurrentComMode
            SC_PpUserRequestLIN_GetCurrentComMode: operation=PpUserRequestLIN.GetCurrentComMode
          written-local-variables:
            access WRITE_irvDoorOldState: accessed-variable=irvDoorOldState
            access WRITE_irvOdometer: accessed-variable=irvOdometer
        RCtApMySwcWdgMTrigger1: mode-access-points=[WdgM_IndividualMode.currentMode, WdgM_GlobalMode.currentMode]
          sync call SC_WdgM_AliveSupervision_CheckpointReached: operation=PpAliveSupervision.CheckpointReached, timeout=0
        ResetEcu
        ServiceRequestNotification_Confirmation
        ServiceRequestNotification_Indication
        ServiceRequestNotification_Supplier_Confirmation
        ServiceRequestNotification_Supplier_Indication
  swc implementation CtApMySwc_Implementation: behavior=CtApMySwc_InternalBehavior
    code-descriptors:
      code Default: artifact-descriptors=autosar-engineering-object={short-label=Default, category=SWSRC}
